# AT32F403Axx_v2 register map
Vendor: Keil; Series: AT32F403A; File version: 1.0
CPU: CM4 r0p1, little endian, no MPU, FPU, 4 interrupt priority bits
Registers are 32-bit, read-write, reset 0x0 unless marked. A register's access mark holds for its fields unless they carry their own. Offsets are from the block's base; [hi:lo] are bit positions.

## TMR10 — General purpose timer
Base 0x40015000
Same registers: TMR13 0x40001C00, TMR14 0x40002000, TMR11 0x40015400
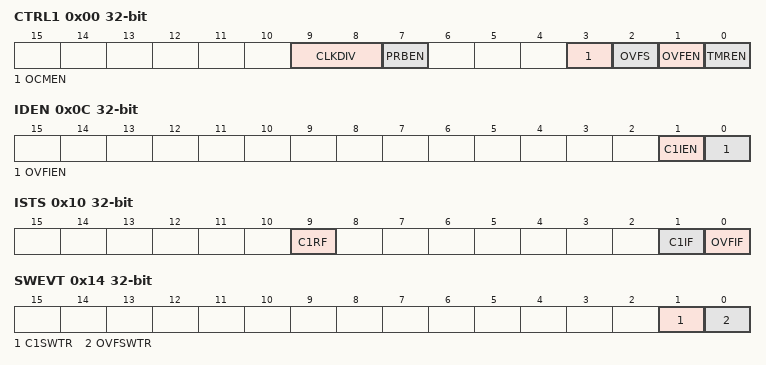
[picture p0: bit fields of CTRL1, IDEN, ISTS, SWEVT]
0x00 CTRL1 — Control register 1
  [9:8] CLKDIV — Clock divider
  [7] PRBEN — Period buffer enable
  [3] OCMEN — One cycle mode enable
  [2] OVFS — Overflow event source
  [1] OVFEN — Overflow event enable
  [0] TMREN — TMR enable
0x0C IDEN — Interrupt/DMA enable register
  [1] C1IEN — Channel 1 interrupt enable
  [0] OVFIEN — Overflow interrupt enable
0x10 ISTS — Interrupt status register
  [9] C1RF — Channel 1 recapture flag
  [1] C1IF — Channel 1 interrupt flag
  [0] OVFIF — Overflow interrupt flag
0x14 SWEVT — Software event register
  [1] C1SWTR — Channel 1 event triggered by software
  [0] OVFSWTR — Overflow event triggered by software
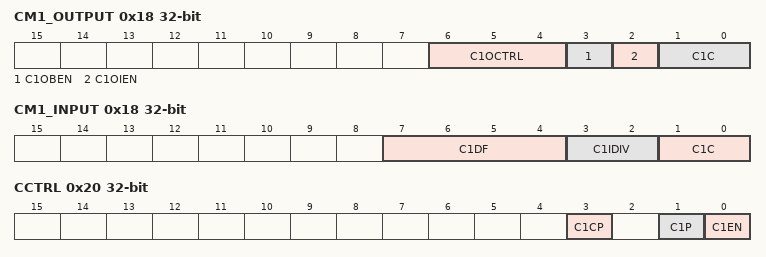
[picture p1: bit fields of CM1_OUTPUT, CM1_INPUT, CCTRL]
0x18 CM1_OUTPUT — Channel output mode register
  [6:4] C1OCTRL — Channel 1 output control
  [3] C1OBEN — Channel 1 output buffer enable
  [2] C1OIEN — Channel 1 output immediately enable
  [1:0] C1C — Channel 1 configure
0x18 CM1_INPUT (alternate view of CM1_OUTPUT) — Channel input mode register 1
  [7:4] C1DF — Channel 1 digital filter
  [3:2] C1IDIV — Channel 1 input divider
  [1:0] C1C — Channel 1 configure
0x20 CCTRL — Channel control register
  [3] C1CP — Channel 1 complementary polarity
  [1] C1P — Channel 1 Polarity
  [0] C1EN — Channel 1 enable
0x24 CVAL — Counter value
  [15:0] CVAL
0x28 DIV — Divider value
  [15:0] DIV
0x2C PR — Period value
  [15:0] PR
0x34 C1DT — Channel 1 data register
  [15:0] C1DT

## ACC — HICK Auto Clock Calibration
Base 0x40015800
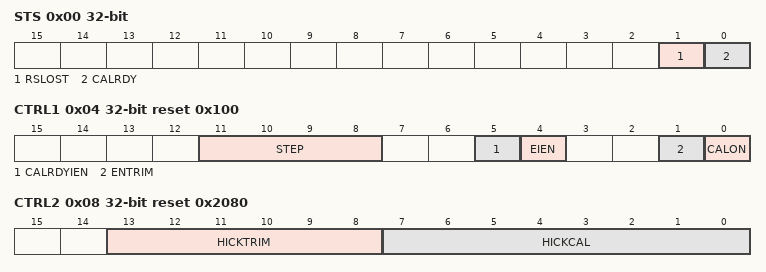
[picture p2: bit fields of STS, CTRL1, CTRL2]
0x00 STS — status register
  [1] RSLOST — Reference Signal Lost
  [0] CALRDY — Internal high-speed clock calibration ready
0x04 CTRL1 reset 0x100 — control register 1
  [11:8] STEP
  [5] CALRDYIEN — CALRDY interrupt enable
  [4] EIEN — RSLOST error interrupt enable
  [1] ENTRIM — Enable trim
  [0] CALON — Calibration on
0x08 CTRL2 reset 0x2080 — control register 2
  [13:8] HICKTRIM ro — Internal high-speed auto clock trimming
  [7:0] HICKCAL ro — Internal high-speed auto clock calibration
0x0C C1 reset 0x1F2C — compare value 1
  [15:0] C1 — Compare 1
0x10 C2 reset 0x1F40 — compare value 2
  [15:0] C2 — Compare 2
0x14 C3 reset 0x1F54 — compare value 3
  [15:0] C3 — Compare 3

## TMR6 — Basic timer
Base 0x40001000
Same registers: TMR7 0x40001400
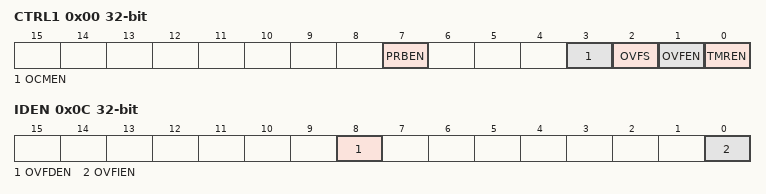
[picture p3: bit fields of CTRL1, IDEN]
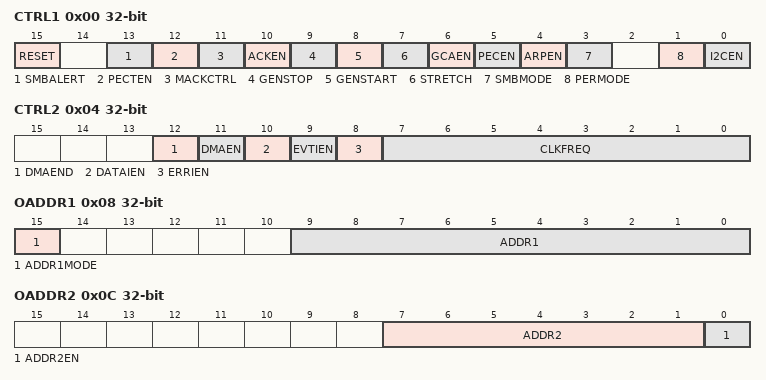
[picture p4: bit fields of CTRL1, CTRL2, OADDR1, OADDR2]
0x00 CTRL1 — Control register 1
  [7] PRBEN — Period buffer enable
  [3] OCMEN — One cycle mode enable
  [2] OVFS — Overflow event source
  [1] OVFEN — Overflow event enable
  [0] TMREN — TMR enable
0x04 CTRL2 — Control register 2
  [6:4] PTOS — Primary TMR output selection
0x0C IDEN — Interrupt/DMA enable register
  [8] OVFDEN — Overflow DMA request enable
  [0] OVFIEN — Overflow interrupt enable
0x10 ISTS — Interrupt status register
  [0] OVFIF — Overflow interrupt flag
0x14 SWEVT — Software event register
  [0] OVFSWTR — Overflow event triggered by software
0x24 CVAL — Counter value
  [15:0] CVAL
0x28 DIV — Divider value
  [15:0] DIV
0x2C PR — Period value
  [15:0] PR

## I2C1 — Inter integrated circuit
Base 0x40005400
Same registers: I2C2 0x40005800, I2C3 0x40015C00
0x00 CTRL1 — Control register 1
  [15] RESET — I2C peripheral reset
  [13] SMBALERT — SMBus alert pin set
  [12] PECTEN — Request PEC transmission enable
  [11] MACKCTRL — Master receiving mode acknowledge control
  [10] ACKEN — Acknowledge enable
  [9] GENSTOP — Stop generation
  [8] GENSTART — Start generation
  [7] STRETCH — Clock stretching mode
  [6] GCAEN — General call address enable
  [5] PECEN — PEC calculation enable
  [4] ARPEN — SMBus address resolution protocol enable
  [3] SMBMODE — SMBus device mode
  [1] PERMODE — I2C peripheral mode
  [0] I2CEN — Peripheral enable
0x04 CTRL2 — Control register 2
  [12] DMAEND — DMA transfer end indication
  [11] DMAEN — DMA transfer enable
  [10] DATAIEN — Data transmission interrupt enable
  [9] EVTIEN — Event interrupt enable
  [8] ERRIEN — Error interrupt enable
  [7:0] CLKFREQ — Input clock frequency
0x08 OADDR1 — Own address register 1
  [15] ADDR1MODE — Address mode
  [9:0] ADDR1 — Own address 1
0x0C OADDR2 — Own address register 2
  [7:1] ADDR2 — Own address 2
  [0] ADDR2EN — Own address 2 enable
0x10 DT — Data register
  [7:0] DT — data register
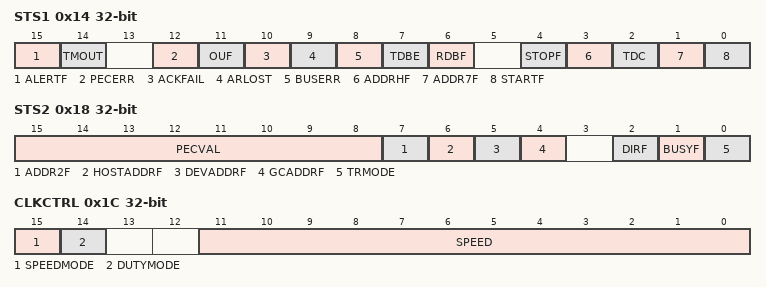
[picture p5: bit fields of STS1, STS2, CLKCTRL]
0x14 STS1 — Status register 1
  [15] ALERTF — SMBus alert
  [14] TMOUT — Timeout error
  [12] PECERR — PEC receive error
  [11] OUF — Overflow or underflow
  [10] ACKFAIL — Acknowledge failure
  [9] ARLOST — Arbitration lost (master mode)
  [8] BUSERR — Bus error
  [7] TDBE ro — Transmit data buffer empty (transmitters)
  [6] RDBF ro — Receive data buffer full (receivers)
  [4] STOPF ro — Stop detection (slave mode)
  [3] ADDRHF ro — address header match (Master mode)
  [2] TDC ro — Transmit data complete
  [1] ADDR7F ro — Address sent (master mode)/matched (slave mode)
  [0] STARTF ro — Start bit (Master mode)
0x18 STS2 ro — Status register 2
  [15:8] PECVAL — PEC value
  [7] ADDR2F — Received address 2
  [6] HOSTADDRF — SMBus host address receiving
  [5] DEVADDRF — SMBus device address receiving
  [4] GCADDRF — General call address reception
  [2] DIRF — Transmission direction
  [1] BUSYF — Bus busy
  [0] TRMODE — Transmission mode
0x1C CLKCTRL — Clock control register
  [15] SPEEDMODE — Speed mode selection
  [14] DUTYMODE — Fast mode duty cycle
  [11:0] SPEED — I2C bus speed config
0x20 TMRISE reset 0x2 — TRISE register
  [5:0] RISETIME — I2C bus rise time

## Notices in the file
Copyright (C) 2012-2014 ARM Limited. All rights reserved.
Purpose: System Viewer Description (SVD) Example (Schema Version 1.1)
This is a description of a none-existent and incomplete device
for demonstration purposes only.
Redistribution and use in source and binary forms, with or without
modification, are permitted provided that the following conditions are met:
- Redistributions of source code must retain the above copyright
notice, this list of conditions and the following disclaimer.
- Redistributions in binary form must reproduce the above copyright
notice, this list of conditions and the following disclaimer in the
documentation and/or other materials provided with the distribution.
- Neither the name of ARM nor the names of its contributors may be used
to endorse or promote products derived from this software without
specific prior written permission.
THIS SOFTWARE IS PROVIDED BY THE COPYRIGHT HOLDERS AND CONTRIBUTORS "AS IS"
AND ANY EXPRESS OR IMPLIED WARRANTIES, INCLUDING, BUT NOT LIMITED TO, THE
IMPLIED WARRANTIES OF MERCHANTABILITY AND FITNESS FOR A PARTICULAR PURPOSE
ARE DISCLAIMED. IN NO EVENT SHALL COPYRIGHT HOLDERS AND CONTRIBUTORS BE
LIABLE FOR ANY DIRECT, INDIRECT, INCIDENTAL, SPECIAL, EXEMPLARY, OR
CONSEQUENTIAL DAMAGES (INCLUDING, BUT NOT LIMITED TO, PROCUREMENT OF
SUBSTITUTE GOODS OR SERVICES; LOSS OF USE, DATA, OR PROFITS; OR BUSINESS
INTERRUPTION) HOWEVER CAUSED AND ON ANY THEORY OF LIABILITY, WHETHER IN
CONTRACT, STRICT LIABILITY, OR TORT (INCLUDING NEGLIGENCE OR OTHERWISE)
ARISING IN ANY WAY OUT OF THE USE OF THIS SOFTWARE, EVEN IF ADVISED OF THE
POSSIBILITY OF SUCH DAMAGE.
